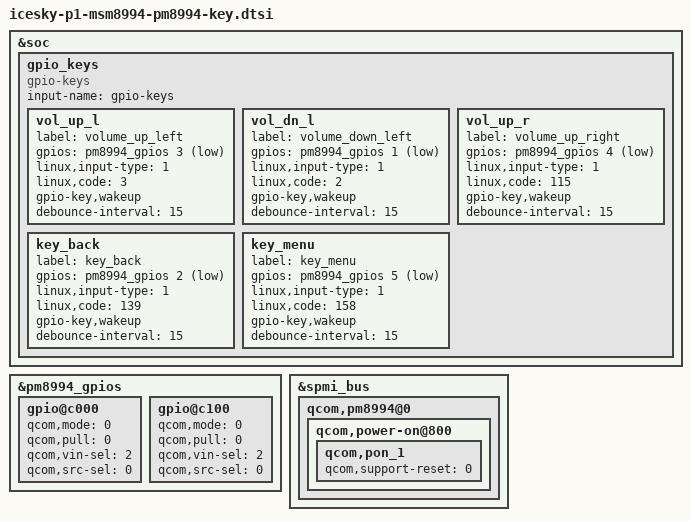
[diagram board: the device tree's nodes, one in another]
/* Copyright (c) 2014, The Linux Foundation. All rights reserved.
 *
 * This program is free software; you can redistribute it and/or modify
 * it under the terms of the GNU General Public License version 2 and
 * only version 2 as published by the Free Software Foundation.
 *
 * This program is distributed in the hope that it will be useful,
 * but WITHOUT ANY WARRANTY; without even the implied warranty of
 * MERCHANTABILITY or FITNESS FOR A PARTICULAR PURPOSE.  See the
 * GNU General Public License for more details.
 */

/* Overlay the msm8994-mtp.dtsi */
&soc {
	gpio_keys {
                compatible = "gpio-keys";
		input-name = "gpio-keys";

		vol_up_l {
			label = "volume_up_left";
			gpios = <&pm8994_gpios 3 0x1>;
			linux,input-type = <1>;
			linux,code = <3>;
			gpio-key,wakeup;
			debounce-interval = <15>;
		};

                vol_dn_l {
			label = "volume_down_left";
			gpios = <&pm8994_gpios 1 0x1>;
			linux,input-type = <1>;
			linux,code = <2>;
			gpio-key,wakeup;
			debounce-interval = <15>;
		};

		vol_up_r {
			label = "volume_up_right";
			gpios = <&pm8994_gpios 4 0x1>;
			linux,input-type = <1>;
			linux,code = <115>;
			gpio-key,wakeup;
			debounce-interval = <15>;
		};

		key_back {
			label = "key_back";
			gpios = <&pm8994_gpios 2 0x1>;
			linux,input-type = <1>;
			linux,code = <139>;
			gpio-key,wakeup;
			debounce-interval = <15>;
		};

		key_menu {
			label = "key_menu";
			gpios = <&pm8994_gpios 5 0x1>;
			linux,input-type = <1>;
			linux,code = <158>;
			gpio-key,wakeup;
			debounce-interval = <15>;
		};
	};
};

&pm8994_gpios {
	gpio@c000 { /* GPIO 1 */
		qcom,mode = <0>;
		qcom,pull = <0>;
		qcom,vin-sel = <2>;
		qcom,src-sel = <0>;
		status = "okay";
	};

	gpio@c100 { /* GPIO 2 */
		qcom,mode = <0>;
		qcom,pull = <0>;
		qcom,vin-sel = <2>;
		qcom,src-sel = <0>;
		status = "okay";
	};
};

/* Overlay the msm-8994.dtsi */
&spmi_bus {
	qcom,pm8994@0 {
		qcom,power-on@800 {
			qcom,pon_1 {
                                qcom,support-reset = <0>;
                        };

		};
	};
};
